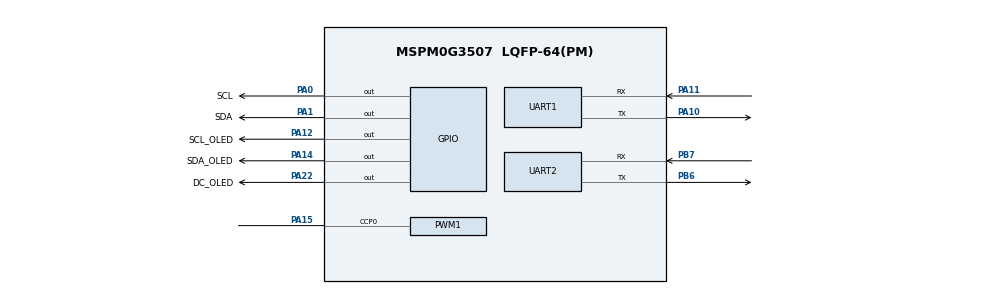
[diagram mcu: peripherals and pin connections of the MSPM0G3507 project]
/**
 * These arguments were used when this file was generated. They will be automatically applied on subsequent loads
 * via the GUI or CLI. Run CLI with '--help' for additional information on how to override these arguments.
 * @cliArgs --device "MSPM0G350X" --part "Default" --package "LQFP-64(PM)" --product "mspm0_sdk@2.10.00.04"
 * @v2CliArgs --device "MSPM0G3507" --package "LQFP-64(PM)" --product "mspm0_sdk@2.10.00.04"
 * @versions {"tool":"1.27.1+4634"}
 */

/**
 * Import the modules used in this configuration.
 */
const ADC12  = scripting.addModule("/ti/driverlib/ADC12", {}, false);
const ADC121 = ADC12.addInstance();
const GPIO   = scripting.addModule("/ti/driverlib/GPIO", {}, false);
const GPIO1  = GPIO.addInstance();
const GPIO2  = GPIO.addInstance();
const PWM    = scripting.addModule("/ti/driverlib/PWM", {}, false);
const PWM1   = PWM.addInstance();
const SYSCTL = scripting.addModule("/ti/driverlib/SYSCTL");
const UART   = scripting.addModule("/ti/driverlib/UART", {}, false);
const UART1  = UART.addInstance();
const UART2  = UART.addInstance();

/**
 * Write custom configuration values to the imported modules.
 */
const gate7  = system.clockTree["MFCLKGATE"];
gate7.enable = true;

ADC121.$name               = "ADC12_0";
ADC121.adcPin0Config.$name = "ti_driverlib_gpio_GPIOPinGeneric6";

const Board = scripting.addModule("/ti/driverlib/Board", {}, false);

GPIO1.$name                          = "I2C";
GPIO1.associatedPins.create(2);
GPIO1.associatedPins[0].$name        = "SCL";
GPIO1.associatedPins[0].initialValue = "SET";
GPIO1.associatedPins[0].ioStructure  = "OD";
GPIO1.associatedPins[0].assignedPort = "PORTA";
GPIO1.associatedPins[0].assignedPin  = "0";
GPIO1.associatedPins[0].pin.$assign  = "PA0";
GPIO1.associatedPins[1].$name        = "SDA";
GPIO1.associatedPins[1].initialValue = "SET";
GPIO1.associatedPins[1].ioStructure  = "OD";
GPIO1.associatedPins[1].assignedPort = "PORTA";
GPIO1.associatedPins[1].assignedPin  = "1";
GPIO1.associatedPins[1].pin.$assign  = "PA1";

GPIO2.$name                          = "OLED";
GPIO2.associatedPins.create(5);
GPIO2.associatedPins[0].$name        = "SCL_OLED";
GPIO2.associatedPins[0].initialValue = "SET";
GPIO2.associatedPins[0].assignedPin  = "12";
GPIO2.associatedPins[0].pin.$assign  = "PA12";
GPIO2.associatedPins[1].$name        = "SDA_OLED";
GPIO2.associatedPins[1].initialValue = "SET";
GPIO2.associatedPins[1].assignedPin  = "14";
GPIO2.associatedPins[1].pin.$assign  = "PA14";
GPIO2.associatedPins[2].$name        = "RES_OLED";
GPIO2.associatedPins[2].initialValue = "SET";
GPIO2.associatedPins[2].assignedPin  = "21";
GPIO2.associatedPins[3].$name        = "DC_OLED";
GPIO2.associatedPins[3].initialValue = "SET";
GPIO2.associatedPins[3].assignedPin  = "22";
GPIO2.associatedPins[3].pin.$assign  = "PA22";
GPIO2.associatedPins[4].$name        = "CS_OLED";
GPIO2.associatedPins[4].initialValue = "SET";
GPIO2.associatedPins[4].assignedPin  = "2";

PWM1.$name                              = "PWM";
PWM1.peripheral.$assign                 = "TIMA1";
PWM1.peripheral.ccp0Pin.$assign         = "PA15";
PWM1.PWM_CHANNEL_0.$name                = "ti_driverlib_pwm_PWMTimerCC0";
PWM1.PWM_CHANNEL_1.$name                = "ti_driverlib_pwm_PWMTimerCC1";
PWM1.ccp0PinConfig.direction            = scripting.forceWrite("OUTPUT");
PWM1.ccp0PinConfig.hideOutputInversion  = scripting.forceWrite(false);
PWM1.ccp0PinConfig.onlyInternalResistor = scripting.forceWrite(false);
PWM1.ccp0PinConfig.passedPeripheralType = scripting.forceWrite("Digital");
PWM1.ccp0PinConfig.$name                = "ti_driverlib_gpio_GPIOPinGeneric4";
PWM1.ccp1PinConfig.direction            = scripting.forceWrite("OUTPUT");
PWM1.ccp1PinConfig.hideOutputInversion  = scripting.forceWrite(false);
PWM1.ccp1PinConfig.onlyInternalResistor = scripting.forceWrite(false);
PWM1.ccp1PinConfig.passedPeripheralType = scripting.forceWrite("Digital");
PWM1.ccp1PinConfig.$name                = "ti_driverlib_gpio_GPIOPinGeneric5";

SYSCTL.forceDefaultClkConfig = true;
SYSCTL.clockTreeEn           = true;

UART1.$name                            = "UART";
UART1.uartClkSrc                       = "MFCLK";
UART1.enabledInterrupts                = ["RX"];
UART1.peripheral.$assign               = "UART0";
UART1.peripheral.rxPin.$assign         = "PA11";
UART1.peripheral.txPin.$assign         = "PA10";
UART1.txPinConfig.direction            = scripting.forceWrite("OUTPUT");
UART1.txPinConfig.hideOutputInversion  = scripting.forceWrite(false);
UART1.txPinConfig.onlyInternalResistor = scripting.forceWrite(false);
UART1.txPinConfig.passedPeripheralType = scripting.forceWrite("Digital");
UART1.txPinConfig.$name                = "ti_driverlib_gpio_GPIOPinGeneric0";
UART1.rxPinConfig.hideOutputInversion  = scripting.forceWrite(false);
UART1.rxPinConfig.onlyInternalResistor = scripting.forceWrite(false);
UART1.rxPinConfig.passedPeripheralType = scripting.forceWrite("Digital");
UART1.rxPinConfig.$name                = "ti_driverlib_gpio_GPIOPinGeneric1";

UART2.$name                            = "UART_PLR";
UART2.uartClkSrc                       = "MFCLK";
UART2.peripheral.$assign               = "UART1";
UART2.peripheral.rxPin.$assign         = "PB7";
UART2.peripheral.txPin.$assign         = "PB6";
UART2.txPinConfig.direction            = scripting.forceWrite("OUTPUT");
UART2.txPinConfig.hideOutputInversion  = scripting.forceWrite(false);
UART2.txPinConfig.onlyInternalResistor = scripting.forceWrite(false);
UART2.txPinConfig.passedPeripheralType = scripting.forceWrite("Digital");
UART2.txPinConfig.$name                = "ti_driverlib_gpio_GPIOPinGeneric2";
UART2.rxPinConfig.hideOutputInversion  = scripting.forceWrite(false);
UART2.rxPinConfig.onlyInternalResistor = scripting.forceWrite(false);
UART2.rxPinConfig.passedPeripheralType = scripting.forceWrite("Digital");
UART2.rxPinConfig.$name                = "ti_driverlib_gpio_GPIOPinGeneric3";

/**
 * Pinmux solution for unlocked pins/peripherals. This ensures that minor changes to the automatic solver in a future
 * version of the tool will not impact the pinmux you originally saw.  These lines can be completely deleted in order to
 * re-solve from scratch.
 */
ADC121.peripheral.$suggestSolution           = "ADC0";
ADC121.peripheral.adcPin0.$suggestSolution   = "PA27";
Board.peripheral.$suggestSolution            = "DEBUGSS";
Board.peripheral.swclkPin.$suggestSolution   = "PA20";
Board.peripheral.swdioPin.$suggestSolution   = "PA19";
GPIO2.associatedPins[2].pin.$suggestSolution = "PA21";
GPIO2.associatedPins[4].pin.$suggestSolution = "PA2";
PWM1.peripheral.ccp1Pin.$suggestSolution     = "PA16";
